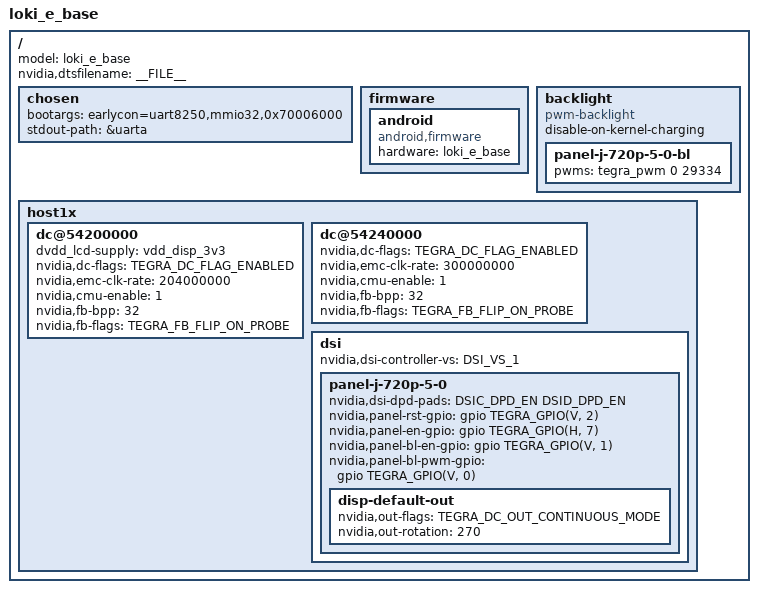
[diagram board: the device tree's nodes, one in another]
/*
 * arch/arm64/boot/dts/tegra210-loki-e-p2530-0131-e00-00.dts
 *
 * Copyright (c) 2014, NVIDIA CORPORATION.  All rights reserved.
 *
 * This program is free software; you can redistribute it and/or modify
 * it under the terms of the GNU General Public License as published by
 * the Free Software Foundation; version 2 of the License.
 *
 * This program is distributed in the hope that it will be useful, but WITHOUT
 * ANY WARRANTY; without even the implied warranty of MERCHANTABILITY or
 * FITNESS FOR A PARTICULAR PURPOSE.  See the GNU General Public License for
 * more details.
 *
 * You should have received a copy of the GNU General Public License along
 * with this program; if not, write to the Free Software Foundation, Inc.,
 * 51 Franklin Street, Fifth Floor, Boston, MA  02110-1301, USA.
 *
 */

#include "tegra210-loki-e-p2530-common.dtsi"
#include "panel-j-720p-5-0.dtsi"
#include "tegra210-platforms/tegra210-loki-e-emc-a00.dtsi"
#include "tegra210-platforms/tegra210-loki-e-touch-p2530-01xx.dtsi"

/ {
	model = "loki_e_base";
	nvidia,dtsfilename = __FILE__;

	chosen {
		bootargs = "earlycon=uart8250,mmio32,0x70006000";
		stdout-path = &uarta;
	};

	firmware {
		android {
			compatible = "android,firmware";
			hardware = "loki_e_base";
		};
	};

	backlight {
		compatible = "pwm-backlight";
		status = "okay";
		disable-on-kernel-charging;
		panel-j-720p-5-0-bl {
			pwms = <&tegra_pwm 0 29334>;
		};
	};

	host1x {
		/* tegradc.0 */
		dc@54200000 {
			status = "okay";
			dvdd_lcd-supply = <&vdd_disp_3v3>;
			nvidia,dc-flags = <TEGRA_DC_FLAG_ENABLED>;
			nvidia,emc-clk-rate = <204000000>;
			nvidia,cmu-enable = <1>;
			nvidia,fb-bpp = <32>; /* bits per pixel */
			nvidia,fb-flags = <TEGRA_FB_FLIP_ON_PROBE>;
		};
		/* tegradc.1 */
		dc@54240000 {
			status = "okay";
			nvidia,dc-flags = <TEGRA_DC_FLAG_ENABLED>;
			nvidia,emc-clk-rate = <300000000>;
			nvidia,cmu-enable = <1>;
			nvidia,fb-bpp = <32>; /* bits per pixel */
			nvidia,fb-flags = <TEGRA_FB_FLIP_ON_PROBE>;
		};
		dsi {
			nvidia,dsi-controller-vs = <DSI_VS_1>;
			status = "okay";
			panel-j-720p-5-0 {
				nvidia,dsi-dpd-pads = <DSIC_DPD_EN DSID_DPD_EN>;
				nvidia,panel-rst-gpio = <&gpio TEGRA_GPIO(V, 2) 0>; /* PV2 */
				nvidia,panel-en-gpio = <&gpio TEGRA_GPIO(H, 7) 0>; /* PH7 */
				nvidia,panel-bl-en-gpio = <&gpio TEGRA_GPIO(V, 1) 0>; /* PV1 */
				nvidia,panel-bl-pwm-gpio = <&gpio TEGRA_GPIO(V, 0) 0>; /* PV0 */
				disp-default-out {
					nvidia,out-flags = <TEGRA_DC_OUT_CONTINUOUS_MODE>;
					nvidia,out-rotation = <270>;
				};
			};
		};
	};
};
